# R40 register map
Vendor: Allwinner; Series: R40; File version: 0.1
CPU: CA7 0, little endian, MPU, FPU, double-precision FPU, 0 interrupt priority bits
Registers are 32-bit, read-write, reset 0x0 unless marked. A register's access mark holds for its fields unless they carry their own. Offsets are from the block's base; [hi:lo] are bit positions.

## OWA
Base 0x01C21000
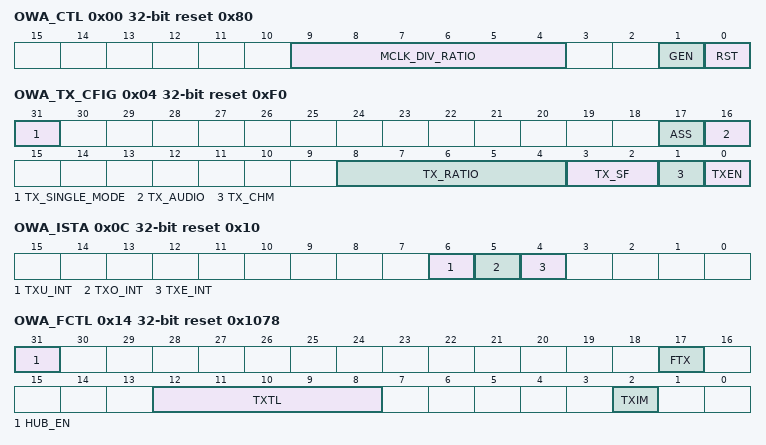
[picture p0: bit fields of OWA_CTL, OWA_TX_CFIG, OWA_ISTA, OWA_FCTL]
0x00 OWA_CTL reset 0x80 — OWA General Control
  [9:4] MCLK_DIV_RATIO — MCLK Divide Ratio Note: Only support 2n divide ratio(n=1~31)
  [1] GEN — Globe Enable A disable on this bit overrides any other block or channel enables and flushes all FIFOs. 0: Disable 1: Enable
    0=Disable; 1=Enable
  [0] RST write-1-clears — Reset 0: Normal 1: Reset
    0=Normal; 1=Reset
0x04 OWA_TX_CFIG reset 0xF0 — OWA TX Configuration Register
  [31] TX_SINGLE_MODE — Tx Single Channel Mode 0: Disable 1: Enable
    0=Disable; 1=Enable
  [17] ASS — Audio sample select with TX FIFO underrun when 0: Sending 0 1: Sending the last audio Note: This bit is only valid in PCM mode
    0=Sending_0; 1=Sending the last audio Note: This bit is only valid in PCM mode
  [16] TX_AUDIO — TX Data Type 0: Linear PCM (Valid bit of both sub-frame set to 0 ) 1: Non-audio(Valid bit of both sub-frame set to 1)
    0=Linear PCM (Valid bit of both sub-frame set to 0 ); 1=non_audio_openingparen_Valid_bit (Non-audio(Valid bit of both sub-frame set to 1))
  [8:4] TX_RATIO — TX Clock Divide Ratio Note: clock divide ratio = TX TATIO +1
  [3:2] TX_SF — TX Sample Format 00: 16bit 01: 20bit 10: 24bit 11: Reserved
    0=_16bit; 1=_20bit; 2=_24bit
  [1] TX_CHM — CHSTMODE 0: Channel status A&B set to 0 1: Channel status A&B generated from TX_CHSTA
    0=Channel_status_A_amp_B_set (Channel status A&B set to 0); 1=Channel_status_A_amp_B_generated (Channel status A&B generated from TX_CHSTA)
  [0] TXEN — 0: Disabled 1: Enabled
    0=Disabled; 1=Enabled
0x0C OWA_ISTA reset 0x10 — OWA Interrupt Status Register
  [6] TXU_INT write-1-clears — TX FIFO Underrun Pending Interrupt 0: No pending IRQ 1: FIFO underrun pending interrupt Write `1` to clear this interrupt.
    0=No pending IRQ; 1=FIFO (FIFO underrun pending interrupt Write `1` to clear this interrupt.)
  [5] TXO_INT write-1-clears — TX FIFO Overrun Pending Interrupt 0: No pending IRQ 1: FIFO overrun pending interrupt Write `1` to clear this interrupt.
    0=No pending IRQ; 1=FIFO (FIFO overrun pending interrupt Write `1` to clear this interrupt.)
  [4] TXE_INT write-1-clears — TX FIFO Empty Pending Interrupt 0: No pending IRQ 1: FIFO empty pending interrupt Write `1` to clear this interrupt or automatically clear if interrupt condition fails.
    0=No pending IRQ; 1=FIFO empty pending interrupt Write `1` to clear this interrupt or automatically clear if interrupt condition fails
0x14 OWA_FCTL reset 0x1078 — OWA FIFO Control Register
  [31] HUB_EN — Audio Hub Enable 0: Disable 1: Enable
    0=Disable; 1=Enable
  [17] FTX write-1-clears — Write `1` to flush TX FIFO, self clear to `0`
  [12:8] TXTL — TX FIFO Empty Trigger Level Interrupt and DMA request trigger level for TX FIFO normal condition Trigger Level = TXTL
  [2] TXIM — TX FIFO Input Mode(Mode0, 1) 0: Valid data at the MSB of OWA_TXFIFO register 1: Valid data at the LSB of OWA_TXFIFO register Example for 20-bits transmitted audio sample: Mode 0: FIFO_I*23:0+ = ,TXFIFO*31:12+, 4`h0- Mode 1: FIFO_I[23:0] = ,TXFIFO*19:0+, 4`h0-
    0=Valid data at the MSB of OWA_TXFIFO register; 1=Valid data at the LSB of OWA_TXFIFO register Example for 20-bits transmitted audio sample: Mode 0: FIFO_I*23:0+ = ,TXFIFO*31:12+, 4`h0- Mode 1: FIFO_I[23:0] = ,TXFIFO*19:0+, 4`h0-
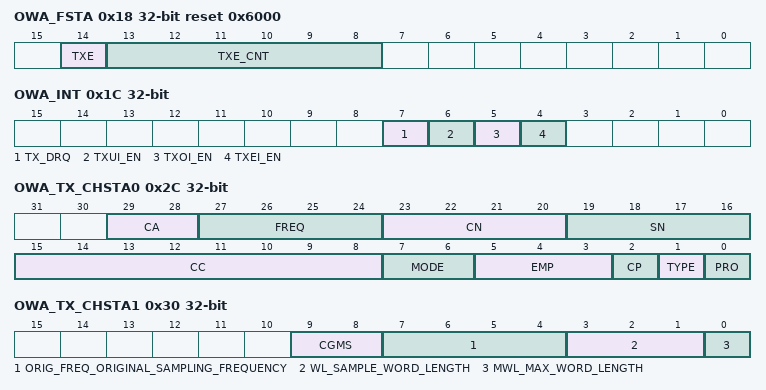
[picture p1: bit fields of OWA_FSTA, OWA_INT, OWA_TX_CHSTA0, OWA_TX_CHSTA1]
0x18 OWA_FSTA reset 0x6000 — OWA FIFO Status Register
  [14] TXE ro — TX FIFO Empty (indicate FIFO is not full) 0: No room for new sample in TX FIFO 1: More than one room for new sample in TX FIFO ( >=1 word )
    0=No room for new sample in TX FIFO; 1=More than one room for new sample in TX FIFO ( >=1 word )
  [13:8] TXE_CNT ro — TX FIFO Empty Space Word counter
0x1C OWA_INT — OWA Interrupt Control Register
  [all] fields
    0=Disable; 1=Enable
  [7] TX_DRQ — TX FIFO Empty DRQ Enable 0: Disable 1: Enable
  [6] TXUI_EN — TX FIFO Underrun Interrupt Enable 0: Disable 1: Enable
  [5] TXOI_EN — TX FIFO Overrun Interrupt Enable 0: Disable 1: Enable
  [4] TXEI_EN — TX FIFO Empty Interrupt Enable 0: Disable 1: Enable
0x20 OWA_TXFIFO
  [31:0] TX_DATA wo — Transmitting A, B channel data should be written this register one by one. The A channel data is first and then the B channel data.
0x24 OWA_TX_CNT — OWA TX Counter Register
  [31:0] TX_CNT — TX Sample Counter The audio sample number of writing into TX FIFO. When one sample is written by DMA or by host IO, the TX sample counter register increases by one. The TX Counter register can be set to any initial value at any time. After been updated by the initial value, the counter register should count on base of this value.
0x2C OWA_TX_CHSTA0 — OWA TX Channel Status Register0
  [29:28] CA — Clock Accuracy 00: Level 2 01: Level 1 10: Level 3 11: Not matched
    0=Level_2; 1=Level_1; 2=Level_3; 3=Not_matched
  [27:24] FREQ — Sampling Frequency 0000: 44.1kHz 0001: not indicated 0010: 48kHz 0011: 32kHz 0100: 22.05kHz 0101: Reserved 0110: 24kHz 0111: Reserved 1000: Reserved 1001: 768kHz 1010: 96kHz 1011: Reserved 1100:176.4kHz 1101: Reserved 1110: 192kHz 1111: Reserved
    0=_44_point_1kHz (44.1kHz); 1=not_indicated; 2=_48kHz; 3=_32kHz; 4=_22_point_05kHz (22.05kHz); 6=_24kHz; 9=_768kHz; 10=_96kHz; 14=_192kHz
  [23:20] CN — Channel Number
  [19:16] SN — Source Number
  [15:8] CC — Category Code Indicates the kind of equipment that generates the digital audio interface signal.
  [7:6] MODE — Mode 00: Default Mode 01~11: Reserved
    0=Default Mode 01~11: Reserved
  [5:3] EMP — Emphasis Additional format information For bit 1 = `0`, Linear PCM audio mode: 000: 2 audio channels without pre-emphasis 001: 2 audio channels with 50 μs / 15 μs pre-emphasis 010: Reserved (for 2 audio channels with pre-emphasis) 011: Reserved (for 2 audio channels with pre-emphasis) 100~111: Reserved For bit 1 = `1`, other than Linear PCM applications: 000: Default state 001~111: Reserved
  [2] CP — Copyright 0: copyright is asserted 1: no copyright is asserted
    0=copyright is asserted; 1=no copyright is asserted
  [1] TYPE — Audio Data Type 0: Linear PCM Samples 1: For none-linear PCM audio such as AC3, DTS, MPEG audio
    0=Linear PCM Samples; 1=For (For none-linear PCM audio such as AC3, DTS, MPEG audio)
  [0] PRO — Application Type 0: Consumer Application 1: Professional Application Note: This bit must be fixed to `0`
    0=Consumer Application; 1=Professional Application Note: This bit must be fixed to `0`
0x30 OWA_TX_CHSTA1 — OWA TX Channel Status Register1
  [9:8] CGMS — CGMS_A 00: Copying is permitted without restriction 01: One generation of copies may be made 10: Condition not be used 11: No copying is permitted
    0=Copying is permitted without restriction; 1=One (One generation of copies may be made); 2=Condition not be used; 3=No copying is permitted
  [7:4] ORIG_FREQ_ORIGINAL_SAMPLING_FREQUENCY — ORIG_FREQ Original Sampling Frequency 0000: Not indicated 0001: 192kHz 0010: 12kHz 0011: 176.4kHz 0100: Reserved 0101: 96kHz 0110: 8kHz 0111: 88.2kHz 1000: 16kHz 1001: 24kHz 1010: 11.025kHz 1011: 22.05kHz 1100: 32kHz 1101: 48kHz 1110: Reserved 1111: 44.1kHz
    0=Not_indicated; 1=_192kHz; 2=_12kHz; 3=_176_point_4kHz (176.4kHz); 5=_96kHz; 6=_8kHz; 7=_88_point_2kHz (88.2kHz); 8=_16kHz; 9=_24kHz; 10=_11_point_025kHz (11.025kHz); 11=_22_point_05kHz (22.05kHz); 12=_32kHz; 13=_48kHz; 15=_44_point_1kHz (44.1kHz)
  [3:1] WL_SAMPLE_WORD_LENGTH — WL Sample Word Length For bit 0 = `0`: 000: not indicated 001: 16 bits 010: 18 bits 100: 19 bits 101: 20 bits 110: 17 bits 111: Reserved For bit 0 = `1`: 000: not indicated 001: 20 bits 010: 22 bits 100: 23 bits 101: 24 bits 110: 21 bits 111: Reserved
  [0] MWL_MAX_WORD_LENGTH — MWL Max Word Length 0: Maximum audio sample word length is 20 bits 1: Maximum audio sample word length is 24 bits
    0=Maximum audio sample word length is 20 bits; 1=Maximum audio sample word length is 24 bits
